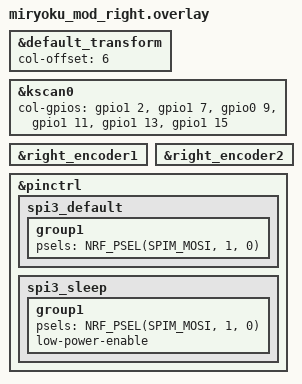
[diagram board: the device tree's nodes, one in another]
#include "miryoku_mod.dtsi"

&default_transform {
    col-offset = <6>;
};


&kscan0 {
    col-gpios
        = <&gpio1 2  (GPIO_ACTIVE_HIGH | GPIO_PULL_DOWN)> // col7 in the schematic
        , <&gpio1 7  (GPIO_ACTIVE_HIGH | GPIO_PULL_DOWN)> // col8 in the schematic
        , <&gpio0 9  (GPIO_ACTIVE_HIGH | GPIO_PULL_DOWN)> // col9 in the schematic
        , <&gpio1 11 (GPIO_ACTIVE_HIGH | GPIO_PULL_DOWN)> // col10 in the schematic
        , <&gpio1 13 (GPIO_ACTIVE_HIGH | GPIO_PULL_DOWN)> // col11 in the schematic
        , <&gpio1 15 (GPIO_ACTIVE_HIGH | GPIO_PULL_DOWN)> // col12 in the schematic
        ;
};

&right_encoder1 {
    status = "okay";
};
&right_encoder2 {
    status = "okay";
};

&pinctrl {
    spi3_default: spi3_default {
        group1 {
            psels = <NRF_PSEL(SPIM_MOSI, 1, 0)>;
        };
    };

    spi3_sleep: spi3_sleep {
        group1 {
            psels = <NRF_PSEL(SPIM_MOSI, 1, 0)>;
            low-power-enable;
        };
    };
};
